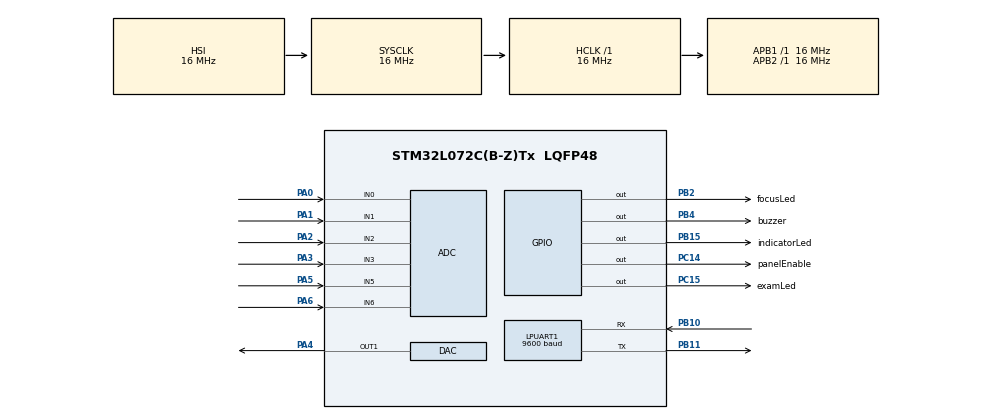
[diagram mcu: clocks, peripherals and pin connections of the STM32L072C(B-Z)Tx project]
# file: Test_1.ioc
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ADC.ContinuousConvMode=DISABLE
ADC.DMAContinuousRequests=ENABLE
Dma.ADC.0.Direction=DMA_PERIPH_TO_MEMORY
Dma.ADC.0.Instance=DMA1_Channel1
Dma.ADC.0.MemDataAlignment=DMA_MDATAALIGN_HALFWORD
Dma.ADC.0.MemInc=DMA_MINC_ENABLE
Dma.ADC.0.Mode=DMA_CIRCULAR
Dma.ADC.0.PeriphDataAlignment=DMA_PDATAALIGN_HALFWORD
Dma.ADC.0.PeriphInc=DMA_PINC_DISABLE
Dma.ADC.0.Priority=DMA_PRIORITY_LOW
Dma.LPUART1_RX.1.Direction=DMA_PERIPH_TO_MEMORY
Dma.LPUART1_RX.1.Instance=DMA1_Channel3
Dma.LPUART1_RX.1.MemDataAlignment=DMA_MDATAALIGN_BYTE
Dma.LPUART1_RX.1.MemInc=DMA_MINC_ENABLE
Dma.LPUART1_RX.1.Mode=DMA_NORMAL
Dma.LPUART1_RX.1.PeriphDataAlignment=DMA_PDATAALIGN_BYTE
Dma.LPUART1_RX.1.PeriphInc=DMA_PINC_DISABLE
Dma.LPUART1_RX.1.Priority=DMA_PRIORITY_LOW
Dma.Request0=ADC
Dma.Request1=LPUART1_RX
LPUART1.BaudRate=9600
LPUART1.WordLength=UART_WORDLENGTH_8B
Mcu.Family=STM32L0
Mcu.Name=STM32L072C(B-Z)Tx
Mcu.Package=LQFP48
NVIC.DMA1_Channel1_IRQn=true\:0\:0\:false\:false\:true\:false\:true
NVIC.DMA1_Channel2_3_IRQn=true\:0\:0\:false\:false\:true\:false\:true
NVIC.TIM7_IRQn=true\:0\:0\:false\:false\:true\:true\:true
PA0.Mode=IN0
PA0.Signal=ADC_IN0
PA1.Mode=IN1
PA1.Signal=ADC_IN1
PA13.Mode=Serial_Wire
PA13.Signal=SYS_SWDIO
PA14.Mode=Serial_Wire
PA14.Signal=SYS_SWCLK
PA2.Mode=IN2
PA2.Signal=ADC_IN2
PA3.Mode=IN3
PA3.Signal=ADC_IN3
PA4.Signal=COMP_DAC1_group
PA5.Mode=IN5
PA5.Signal=ADC_IN5
PA6.Mode=IN6
PA6.Signal=ADC_IN6
PB10.Mode=Asynchronous
PB10.Signal=LPUART1_RX
PB11.Mode=Asynchronous
PB11.Signal=LPUART1_TX
PB15.GPIO_Label=indicatorLed
PB15.Signal=GPIO_Output
PB2.GPIO_Label=focusLed
PB2.Signal=GPIO_Output
PB4.GPIO_Label=buzzer
PB4.Signal=GPIO_Output
PC14-OSC32_IN.GPIO_Label=panelEnable
PC14-OSC32_IN.Signal=GPIO_Output
PC15-OSC32_OUT.GPIO_Label=examLed
PC15-OSC32_OUT.Signal=GPIO_Output
ProjectManager.HeapSize=0x200
ProjectManager.StackSize=0x400
ProjectManager.TargetToolchain=MDK-ARM V5
RCC.AHBFreq_Value=16000000
RCC.APB1Freq_Value=16000000
RCC.APB1TimFreq_Value=16000000
RCC.APB2Freq_Value=16000000
RCC.APB2TimFreq_Value=16000000
RCC.HCLKFreq_Value=16000000
RCC.HSE_VALUE=8000000
RCC.HSI16_VALUE=16000000
RCC.HSI48_VALUE=48000000
RCC.HSI_VALUE=16000000
RCC.LSE_VALUE=32768
RCC.MSI_VALUE=2097000
RCC.SYSCLKFreq_VALUE=16000000
RCC.SYSCLKSource=RCC_SYSCLKSOURCE_HSI
RCC.VCOOutputFreq_Value=48000000
SH.COMP_DAC1_group.0=DAC_OUT1,DAC_OUT1
VP_TIM7_VS_ClockSourceINT.Mode=Enable_Timer
board=custom

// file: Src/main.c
/* USER CODE BEGIN Header */
/**
  ******************************************************************************
  * @file           : main.c
  * @brief          : Main program body
  ******************************************************************************
  * @attention
  *
  * <h2><center>&copy; Copyright (c) 2021 STMicroelectronics.
  * All rights reserved.</center></h2>
  *
  * This software component is licensed by ST under BSD 3-Clause license,
  * the "License"; You may not use this file except in compliance with the
  * License. You may obtain a copy of the License at:
  *                        opensource.org/licenses/BSD-3-Clause
  *
  ******************************************************************************
  */
/* USER CODE END Header */

#include "main.h"
#include "math.h"
#include "stdio.h"

ADC_HandleTypeDef hadc;
DMA_HandleTypeDef hdma_adc;

DAC_HandleTypeDef hdac;

UART_HandleTypeDef hlpuart1;
DMA_HandleTypeDef hdma_lpuart1_rx;

TIM_HandleTypeDef htim7;

/* USER CODE BEGIN PV */
uint16_t adc_buf[6], adc_values[6];
int dac_value = 0;
uint8_t rx_buffer[] = {0};
char durum;

/* USER CODE END PV */

void SystemClock_Config(void);
static void MX_GPIO_Init(void);
static void MX_DMA_Init(void);
static void MX_DAC_Init(void);
static void MX_ADC_Init(void);
static void MX_LPUART1_UART_Init(void);
static void MX_TIM7_Init(void);
/* USER CODE BEGIN PFP */
/*void measure_skin_temp()
{
	HAL_ADC_Start(&hadc);
	R = ((4095-adc_buf[2])*4120)/adc_buf[2];
	T = 1/((A/pow(10,3))+((B/pow(10,4))*log(R))+((C/pow(10,7))*pow((log(R)),3)));
	T_Celcius = T-273.95;
	sprintf(string_t_celcius, "%2.1f", T_Celcius);
	send_data[8]=string_t_celcius[0];
	send_data[9]=string_t_celcius[1];
	send_data[10]=string_t_celcius[2];
	send_data[11]=string_t_celcius[3];
	HAL_UART_Transmit(&hlpuart1, send_data, sizeof(send_data), 100);
}*/

/* USER CODE END PFP */

int main(void)
{

  /* MCU Configuration--------------------------------------------------------*/

  /* Reset of all peripherals, Initializes the Flash interface and the Systick. */
  HAL_Init();

  /* Configure the system clock */
  SystemClock_Config();

  /* Initialize all configured peripherals */
  MX_GPIO_Init();
  MX_DMA_Init();
  MX_DAC_Init();
  MX_ADC_Init();
  MX_LPUART1_UART_Init();
  MX_TIM7_Init();
  /* USER CODE BEGIN 2 */
	while(HAL_ADCEx_Calibration_Start(&hadc, ADC_SINGLE_ENDED) != HAL_OK){};	// Kalibrasyon yap
	HAL_ADC_Start_DMA(&hadc, (uint32_t*)adc_buf, 6);
	HAL_DAC_Start(&hdac, DAC_CHANNEL_1);
	HAL_DAC_SetValue(&hdac, DAC_CHANNEL_1,DAC_ALIGN_12B_R,dac_value);
	HAL_UART_Receive_DMA (&hlpuart1, rx_buffer, 1);
	HAL_TIM_Base_Start_IT(&htim7);
  /* USER CODE END 2 */

  /* Infinite loop */
  while (1)
  {
		//measure_skin_temp();
		durum = rx_buffer[0];
		switch(durum)
		{
			case '0':
				HAL_GPIO_WritePin(examLed_GPIO_Port, examLed_Pin, GPIO_PIN_RESET);
				break;
			case '1':
				HAL_GPIO_WritePin(examLed_GPIO_Port, examLed_Pin, GPIO_PIN_SET);
				break;
			case '2':
				HAL_GPIO_WritePin(focusLed_GPIO_Port, focusLed_Pin, GPIO_PIN_RESET);
				break;
			case '3':
				HAL_GPIO_WritePin(focusLed_GPIO_Port, focusLed_Pin, GPIO_PIN_SET);
				break;
			case '4':
				HAL_GPIO_WritePin(panelEnable_GPIO_Port, panelEnable_Pin, GPIO_PIN_RESET);
				break;
			case '5':
				HAL_GPIO_WritePin(panelEnable_GPIO_Port, panelEnable_Pin, GPIO_PIN_SET);
				break;
		}
  }
}

void SystemClock_Config(void)
{
  RCC_OscInitTypeDef RCC_OscInitStruct = {0};
  RCC_ClkInitTypeDef RCC_ClkInitStruct = {0};
  RCC_PeriphCLKInitTypeDef PeriphClkInit = {0};

  /** Configure the main internal regulator output voltage
  */
  __HAL_PWR_VOLTAGESCALING_CONFIG(PWR_REGULATOR_VOLTAGE_SCALE1);
  /** Initializes the CPU, AHB and APB busses clocks
  */
  RCC_OscInitStruct.OscillatorType = RCC_OSCILLATORTYPE_HSI;
  RCC_OscInitStruct.HSIState = RCC_HSI_ON;
  RCC_OscInitStruct.HSICalibrationValue = RCC_HSICALIBRATION_DEFAULT;
  RCC_OscInitStruct.PLL.PLLState = RCC_PLL_NONE;
  if (HAL_RCC_OscConfig(&RCC_OscInitStruct) != HAL_OK)
  {
    Error_Handler();
  }
  /** Initializes the CPU, AHB and APB busses clocks
  */
  RCC_ClkInitStruct.ClockType = RCC_CLOCKTYPE_HCLK|RCC_CLOCKTYPE_SYSCLK
                              |RCC_CLOCKTYPE_PCLK1|RCC_CLOCKTYPE_PCLK2;
  RCC_ClkInitStruct.SYSCLKSource = RCC_SYSCLKSOURCE_HSI;
  RCC_ClkInitStruct.AHBCLKDivider = RCC_SYSCLK_DIV1;
  RCC_ClkInitStruct.APB1CLKDivider = RCC_HCLK_DIV1;
  RCC_ClkInitStruct.APB2CLKDivider = RCC_HCLK_DIV1;

  if (HAL_RCC_ClockConfig(&RCC_ClkInitStruct, FLASH_LATENCY_0) != HAL_OK)
  {
    Error_Handler();
  }
  PeriphClkInit.PeriphClockSelection = RCC_PERIPHCLK_LPUART1;
  PeriphClkInit.Lpuart1ClockSelection = RCC_LPUART1CLKSOURCE_PCLK1;
  if (HAL_RCCEx_PeriphCLKConfig(&PeriphClkInit) != HAL_OK)
  {
    Error_Handler();
  }
}

static void MX_ADC_Init(void)
{

  ADC_ChannelConfTypeDef sConfig = {0};

  /** Configure the global features of the ADC (Clock, Resolution, Data Alignment and number of conversion)
  */
  hadc.Instance = ADC1;
  hadc.Init.OversamplingMode = DISABLE;
  hadc.Init.ClockPrescaler = ADC_CLOCK_SYNC_PCLK_DIV1;
  hadc.Init.Resolution = ADC_RESOLUTION_12B;
  hadc.Init.SamplingTime = ADC_SAMPLETIME_1CYCLE_5;
  hadc.Init.ScanConvMode = ADC_SCAN_DIRECTION_FORWARD;
  hadc.Init.DataAlign = ADC_DATAALIGN_RIGHT;
  hadc.Init.ContinuousConvMode = DISABLE;
  hadc.Init.DiscontinuousConvMode = DISABLE;
  hadc.Init.ExternalTrigConvEdge = ADC_EXTERNALTRIGCONVEDGE_NONE;
  hadc.Init.ExternalTrigConv = ADC_SOFTWARE_START;
  hadc.Init.DMAContinuousRequests = ENABLE;
  hadc.Init.EOCSelection = ADC_EOC_SINGLE_CONV;
  hadc.Init.Overrun = ADC_OVR_DATA_PRESERVED;
  hadc.Init.LowPowerAutoWait = DISABLE;
  hadc.Init.LowPowerFrequencyMode = DISABLE;
  hadc.Init.LowPowerAutoPowerOff = DISABLE;
  if (HAL_ADC_Init(&hadc) != HAL_OK)
  {
    Error_Handler();
  }
  /** Configure for the selected ADC regular channel to be converted.
  */
  sConfig.Channel = ADC_CHANNEL_0;
  sConfig.Rank = ADC_RANK_CHANNEL_NUMBER;
  if (HAL_ADC_ConfigChannel(&hadc, &sConfig) != HAL_OK)
  {
    Error_Handler();
  }
  /** Configure for the selected ADC regular channel to be converted.
  */
  sConfig.Channel = ADC_CHANNEL_1;
  if (HAL_ADC_ConfigChannel(&hadc, &sConfig) != HAL_OK)
  {
    Error_Handler();
  }
  /** Configure for the selected ADC regular channel to be converted.
  */
  sConfig.Channel = ADC_CHANNEL_2;
  if (HAL_ADC_ConfigChannel(&hadc, &sConfig) != HAL_OK)
  {
    Error_Handler();
  }
  /** Configure for the selected ADC regular channel to be converted.
  */
  sConfig.Channel = ADC_CHANNEL_3;
  if (HAL_ADC_ConfigChannel(&hadc, &sConfig) != HAL_OK)
  {
    Error_Handler();
  }
  /** Configure for the selected ADC regular channel to be converted.
  */
  sConfig.Channel = ADC_CHANNEL_5;
  if (HAL_ADC_ConfigChannel(&hadc, &sConfig) != HAL_OK)
  {
    Error_Handler();
  }
  /** Configure for the selected ADC regular channel to be converted.
  */
  sConfig.Channel = ADC_CHANNEL_6;
  if (HAL_ADC_ConfigChannel(&hadc, &sConfig) != HAL_OK)
  {
    Error_Handler();
  }

}

static void MX_DAC_Init(void)
{

  DAC_ChannelConfTypeDef sConfig = {0};

  /** DAC Initialization
  */
  hdac.Instance = DAC;
  if (HAL_DAC_Init(&hdac) != HAL_OK)
  {
    Error_Handler();
  }
  /** DAC channel OUT1 config
  */
  sConfig.DAC_Trigger = DAC_TRIGGER_NONE;
  sConfig.DAC_OutputBuffer = DAC_OUTPUTBUFFER_ENABLE;
  if (HAL_DAC_ConfigChannel(&hdac, &sConfig, DAC_CHANNEL_1) != HAL_OK)
  {
    Error_Handler();
  }

}

static void MX_LPUART1_UART_Init(void)
{

  hlpuart1.Instance = LPUART1;
  hlpuart1.Init.BaudRate = 9600;
  hlpuart1.Init.WordLength = UART_WORDLENGTH_8B;
  hlpuart1.Init.StopBits = UART_STOPBITS_1;
  hlpuart1.Init.Parity = UART_PARITY_NONE;
  hlpuart1.Init.Mode = UART_MODE_TX_RX;
  hlpuart1.Init.HwFlowCtl = UART_HWCONTROL_NONE;
  hlpuart1.Init.OneBitSampling = UART_ONE_BIT_SAMPLE_DISABLE;
  hlpuart1.AdvancedInit.AdvFeatureInit = UART_ADVFEATURE_NO_INIT;
  if (HAL_UART_Init(&hlpuart1) != HAL_OK)
  {
    Error_Handler();
  }

}

static void MX_TIM7_Init(void)
{

  TIM_MasterConfigTypeDef sMasterConfig = {0};

  htim7.Instance = TIM7;
  htim7.Init.Prescaler = 3999;
  htim7.Init.CounterMode = TIM_COUNTERMODE_UP;
  htim7.Init.Period = 3999;
  htim7.Init.AutoReloadPreload = TIM_AUTORELOAD_PRELOAD_DISABLE;
  if (HAL_TIM_Base_Init(&htim7) != HAL_OK)
  {
    Error_Handler();
  }
  sMasterConfig.MasterOutputTrigger = TIM_TRGO_RESET;
  sMasterConfig.MasterSlaveMode = TIM_MASTERSLAVEMODE_DISABLE;
  if (HAL_TIMEx_MasterConfigSynchronization(&htim7, &sMasterConfig) != HAL_OK)
  {
    Error_Handler();
  }

}

static void MX_DMA_Init(void)
{
  /* DMA controller clock enable */
  __HAL_RCC_DMA1_CLK_ENABLE();

  /* DMA interrupt init */
  /* DMA1_Channel1_IRQn interrupt configuration */
  HAL_NVIC_SetPriority(DMA1_Channel1_IRQn, 0, 0);
  HAL_NVIC_EnableIRQ(DMA1_Channel1_IRQn);
  /* DMA1_Channel2_3_IRQn interrupt configuration */
  HAL_NVIC_SetPriority(DMA1_Channel2_3_IRQn, 0, 0);
  HAL_NVIC_EnableIRQ(DMA1_Channel2_3_IRQn);

}

static void MX_GPIO_Init(void)
{
  GPIO_InitTypeDef GPIO_InitStruct = {0};

  /* GPIO Ports Clock Enable */
  __HAL_RCC_GPIOC_CLK_ENABLE();
  __HAL_RCC_GPIOA_CLK_ENABLE();
  __HAL_RCC_GPIOB_CLK_ENABLE();

  /*Configure GPIO pin Output Level */
  HAL_GPIO_WritePin(GPIOC, panelEnable_Pin|examLed_Pin, GPIO_PIN_RESET);

  /*Configure GPIO pin Output Level */
  HAL_GPIO_WritePin(GPIOB, focusLed_Pin|indicatorLed_Pin|buzzer_Pin, GPIO_PIN_RESET);

  /*Configure GPIO pins : panelEnable_Pin examLed_Pin */
  GPIO_InitStruct.Pin = panelEnable_Pin|examLed_Pin;
  GPIO_InitStruct.Mode = GPIO_MODE_OUTPUT_PP;
  GPIO_InitStruct.Pull = GPIO_NOPULL;
  GPIO_InitStruct.Speed = GPIO_SPEED_FREQ_LOW;
  HAL_GPIO_Init(GPIOC, &GPIO_InitStruct);

  /*Configure GPIO pins : focusLed_Pin indicatorLed_Pin buzzer_Pin */
  GPIO_InitStruct.Pin = focusLed_Pin|indicatorLed_Pin|buzzer_Pin;
  GPIO_InitStruct.Mode = GPIO_MODE_OUTPUT_PP;
  GPIO_InitStruct.Pull = GPIO_NOPULL;
  GPIO_InitStruct.Speed = GPIO_SPEED_FREQ_LOW;
  HAL_GPIO_Init(GPIOB, &GPIO_InitStruct);

}

/* USER CODE BEGIN 4 */
void HAL_UART_RxCpltCallback(UART_HandleTypeDef *huart)
{
	HAL_UART_Receive_DMA(&hlpuart1, rx_buffer, 1);
}

/* USER CODE END 4 */

void Error_Handler(void)
{
}

/************************ (C) COPYRIGHT STMicroelectronics *****END OF FILE****/
